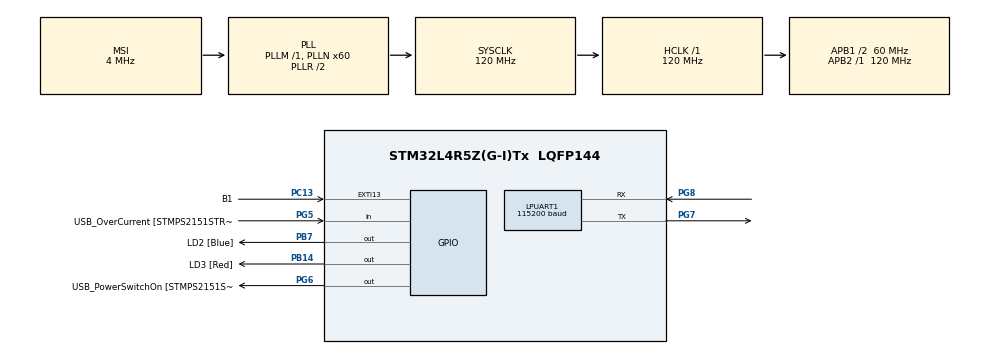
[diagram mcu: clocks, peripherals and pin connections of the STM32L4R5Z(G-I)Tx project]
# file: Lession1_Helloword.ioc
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LPUART1.BaudRate=115200
LPUART1.WordLength=UART_WORDLENGTH_8B
Mcu.Family=STM32L4
Mcu.Name=STM32L4R5Z(G-I)Tx
Mcu.Package=LQFP144
NVIC.LPUART1_IRQn=true\:0\:0\:false\:false\:true\:true
NVIC.PriorityGroup=NVIC_PRIORITYGROUP_4
PA10.GPIO_Label=USB_ID
PA10.Signal=USB_OTG_FS_ID
PA11.GPIO_Label=USB_DM
PA11.Signal=USB_OTG_FS_DM
PA12.GPIO_Label=USB_DP
PA12.Signal=USB_OTG_FS_DP
PA13\ (JTMS/SWDIO).GPIO_Label=TMS
PA13\ (JTMS/SWDIO).Mode=Trace_Asynchronous_SW
PA13\ (JTMS/SWDIO).Signal=SYS_JTMS-SWDIO
PA14\ (JTCK/SWCLK).GPIO_Label=TCK
PA14\ (JTCK/SWCLK).Mode=Trace_Asynchronous_SW
PA14\ (JTCK/SWCLK).Signal=SYS_JTCK-SWCLK
PA8.GPIO_Label=USB_SOF [TP1]
PA8.Signal=USB_OTG_FS_SOF
PA9.GPIO_Label=USB_VBUS
PA9.Signal=USB_OTG_FS_VBUS
PB14.GPIO_Label=LD3 [Red]
PB14.Signal=GPIO_Output
PB3\ (JTDO/TRACESWO).GPIO_Label=SWO
PB3\ (JTDO/TRACESWO).Mode=Trace_Asynchronous_SW
PB3\ (JTDO/TRACESWO).Signal=SYS_JTDO-SWO
PB7.GPIO_Label=LD2 [Blue]
PB7.Signal=GPIO_Output
PC13.GPIO_Label=B1
PC13.Signal=GPXTI13
PC14-OSC32_IN\ (PC14).Mode=LSE-External-Oscillator
PC14-OSC32_IN\ (PC14).Signal=RCC_OSC32_IN
PC15-OSC32_OUT\ (PC15).Mode=LSE-External-Oscillator
PC15-OSC32_OUT\ (PC15).Signal=RCC_OSC32_OUT
PD8.GPIO_Label=STLK_RX [STM32F103CBT6_PA3]
PD8.Signal=USART3_TX
PD9.GPIO_Label=STLK_TX [STM32F103CBT6_PA2]
PD9.Signal=USART3_RX
PG5.GPIO_Label=USB_OverCurrent [STMPS2151STR_FAULT]
PG5.Signal=GPIO_Input
PG6.GPIO_Label=USB_PowerSwitchOn [STMPS2151STR_En]
PG6.Signal=GPIO_Output
PG7.Mode=Asynchronous
PG7.Signal=LPUART1_TX
PG8.Mode=Asynchronous
PG8.Signal=LPUART1_RX
PH0-OSC_IN\ (PH0).Mode=HSE-External-Oscillator
PH0-OSC_IN\ (PH0).Signal=RCC_OSC_IN
PH1-OSC_OUT\ (PH1).Mode=HSE-External-Oscillator
PH1-OSC_OUT\ (PH1).Signal=RCC_OSC_OUT
ProjectManager.HeapSize=0x2000
ProjectManager.StackSize=0x4000
ProjectManager.TargetToolchain=MDK-ARM V5
RCC.48MHZClocksFreq_Value=24000000
RCC.AHBFreq_Value=120000000
RCC.APB1CLKDivider=RCC_HCLK_DIV2
RCC.APB1Freq_Value=60000000
RCC.APB1TimFreq_Value=120000000
RCC.APB2Freq_Value=120000000
RCC.APB2TimFreq_Value=120000000
RCC.CortexFreq_Value=120000000
RCC.HCLKFreq_Value=120000000
RCC.HSE_VALUE=8000000
RCC.HSI48_VALUE=48000000
RCC.HSI_VALUE=16000000
RCC.MSI_VALUE=4000000
RCC.PLLMUL=RCC_PLL_MUL9
RCC.PLLN=60
RCC.PRESCALERUSB=RCC_USBCLKSOURCE_PLL_DIV1_5
RCC.SYSCLKFreq_VALUE=120000000
RCC.SYSCLKSource=RCC_SYSCLKSOURCE_PLLCLK
RCC.SYSCLKSourceVirtual=RCC_SYSCLKSOURCE_PLLCLK
RCC.USBFreq_Value=16000000
RCC.VCOOutputFreq_Value=240000000
board=NUCLEO-L4R5ZI

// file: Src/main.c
/**
  ******************************************************************************
  * @file           : main.c
  * @brief          : Main program body
  ******************************************************************************
  ** This notice applies to any and all portions of this file
  * that are not between comment pairs USER CODE BEGIN and
  * USER CODE END. Other portions of this file, whether
  * inserted by the user or by software development tools
  * are owned by their respective copyright owners.
  *
  * COPYRIGHT(c) 2020 STMicroelectronics
  *
  * Redistribution and use in source and binary forms, with or without modification,
  * are permitted provided that the following conditions are met:
  *   1. Redistributions of source code must retain the above copyright notice,
  *      this list of conditions and the following disclaimer.
  *   2. Redistributions in binary form must reproduce the above copyright notice,
  *      this list of conditions and the following disclaimer in the documentation
  *      and/or other materials provided with the distribution.
  *   3. Neither the name of STMicroelectronics nor the names of its contributors
  *      may be used to endorse or promote products derived from this software
  *      without specific prior written permission.
  *
  * THIS SOFTWARE IS PROVIDED BY THE COPYRIGHT HOLDERS AND CONTRIBUTORS "AS IS"
  * AND ANY EXPRESS OR IMPLIED WARRANTIES, INCLUDING, BUT NOT LIMITED TO, THE
  * IMPLIED WARRANTIES OF MERCHANTABILITY AND FITNESS FOR A PARTICULAR PURPOSE ARE
  * DISCLAIMED. IN NO EVENT SHALL THE COPYRIGHT HOLDER OR CONTRIBUTORS BE LIABLE
  * FOR ANY DIRECT, INDIRECT, INCIDENTAL, SPECIAL, EXEMPLARY, OR CONSEQUENTIAL
  * DAMAGES (INCLUDING, BUT NOT LIMITED TO, PROCUREMENT OF SUBSTITUTE GOODS OR
  * SERVICES; LOSS OF USE, DATA, OR PROFITS; OR BUSINESS INTERRUPTION) HOWEVER
  * CAUSED AND ON ANY THEORY OF LIABILITY, WHETHER IN CONTRACT, STRICT LIABILITY,
  * OR TORT (INCLUDING NEGLIGENCE OR OTHERWISE) ARISING IN ANY WAY OUT OF THE USE
  * OF THIS SOFTWARE, EVEN IF ADVISED OF THE POSSIBILITY OF SUCH DAMAGE.
  *
  ******************************************************************************
  */
#include "main.h"
#include "stm32l4xx_hal.h"
#include "usart.h"
#include "gpio.h"

/* USER CODE BEGIN Includes */
#include "LogFile.h"
#include "LessionInterface.h"
/* USER CODE END Includes */

/* USER CODE BEGIN PV */
/* Private variables ---------------------------------------------------------*/

/* USER CODE END PV */

void SystemClock_Config(void);

/* USER CODE BEGIN PFP */
/* Private function prototypes -----------------------------------------------*/

/* USER CODE END PFP */

int main(void)
{

  /* MCU Configuration----------------------------------------------------------*/

  /* Reset of all peripherals, Initializes the Flash interface and the Systick. */
  HAL_Init();

  /* Configure the system clock */
  SystemClock_Config();

  /* Initialize all configured peripherals */
  MX_GPIO_Init();
  MX_LPUART1_UART_Init();
  /* USER CODE BEGIN 2 */
	RunLession1();
	RunLession3();
  /* USER CODE END 2 */

  /* Infinite loop */
  while (1)
  {

  /* USER CODE BEGIN 3 */
	RunLession2();
  }
  /* USER CODE END 3 */

}

void SystemClock_Config(void)
{

  RCC_OscInitTypeDef RCC_OscInitStruct;
  RCC_ClkInitTypeDef RCC_ClkInitStruct;
  RCC_PeriphCLKInitTypeDef PeriphClkInit;

    /**Configure the main internal regulator output voltage
    */
  if (HAL_PWREx_ControlVoltageScaling(PWR_REGULATOR_VOLTAGE_SCALE1_BOOST) != HAL_OK)
  {
    _Error_Handler(__FILE__, __LINE__);
  }

    /**Initializes the CPU, AHB and APB busses clocks
    */
  RCC_OscInitStruct.OscillatorType = RCC_OSCILLATORTYPE_MSI;
  RCC_OscInitStruct.MSIState = RCC_MSI_ON;
  RCC_OscInitStruct.MSICalibrationValue = 0;
  RCC_OscInitStruct.MSIClockRange = RCC_MSIRANGE_6;
  RCC_OscInitStruct.PLL.PLLState = RCC_PLL_ON;
  RCC_OscInitStruct.PLL.PLLSource = RCC_PLLSOURCE_MSI;
  RCC_OscInitStruct.PLL.PLLM = 1;
  RCC_OscInitStruct.PLL.PLLN = 60;
  RCC_OscInitStruct.PLL.PLLP = RCC_PLLP_DIV2;
  RCC_OscInitStruct.PLL.PLLQ = RCC_PLLQ_DIV2;
  RCC_OscInitStruct.PLL.PLLR = RCC_PLLR_DIV2;
  if (HAL_RCC_OscConfig(&RCC_OscInitStruct) != HAL_OK)
  {
    _Error_Handler(__FILE__, __LINE__);
  }

    /**Initializes the CPU, AHB and APB busses clocks
    */
  RCC_ClkInitStruct.ClockType = RCC_CLOCKTYPE_HCLK|RCC_CLOCKTYPE_SYSCLK
                              |RCC_CLOCKTYPE_PCLK1|RCC_CLOCKTYPE_PCLK2;
  RCC_ClkInitStruct.SYSCLKSource = RCC_SYSCLKSOURCE_PLLCLK;
  RCC_ClkInitStruct.AHBCLKDivider = RCC_SYSCLK_DIV1;
  RCC_ClkInitStruct.APB1CLKDivider = RCC_HCLK_DIV2;
  RCC_ClkInitStruct.APB2CLKDivider = RCC_HCLK_DIV1;

  if (HAL_RCC_ClockConfig(&RCC_ClkInitStruct, FLASH_LATENCY_5) != HAL_OK)
  {
    _Error_Handler(__FILE__, __LINE__);
  }

  PeriphClkInit.PeriphClockSelection = RCC_PERIPHCLK_LPUART1;
  PeriphClkInit.Lpuart1ClockSelection = RCC_LPUART1CLKSOURCE_PCLK1;
  if (HAL_RCCEx_PeriphCLKConfig(&PeriphClkInit) != HAL_OK)
  {
    _Error_Handler(__FILE__, __LINE__);
  }

    /**Configure the Systick interrupt time
    */
  HAL_SYSTICK_Config(HAL_RCC_GetHCLKFreq()/1000);

    /**Configure the Systick
    */
  HAL_SYSTICK_CLKSourceConfig(SYSTICK_CLKSOURCE_HCLK);

  /* SysTick_IRQn interrupt configuration */
  HAL_NVIC_SetPriority(SysTick_IRQn, 0, 0);
}

void _Error_Handler(char *file, int line)
{
  /* USER CODE BEGIN Error_Handler_Debug */
  /* User can add his own implementation to report the HAL error return state */
		LOG_ERROR("Error Log");
  /* USER CODE END Error_Handler_Debug */
}

/************************ (C) COPYRIGHT STMicroelectronics *****END OF FILE****/
